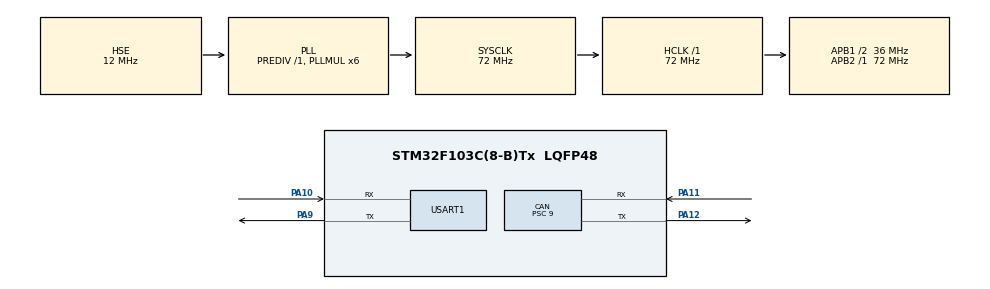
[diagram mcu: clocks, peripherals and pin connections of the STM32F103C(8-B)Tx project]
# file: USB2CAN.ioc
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Mcu.Family=STM32F1
Dma.MEMTOMEM.2.PeriphInc=DMA_PINC_ENABLE
RCC.PLLSourceVirtual=RCC_PLLSOURCE_HSE
Dma.USART1_TX.1.Instance=DMA1_Channel4
Dma.MEMTOMEM.2.MemDataAlignment=DMA_MDATAALIGN_BYTE
NVIC.DMA1_Channel5_IRQn=true\:0\:0\:false\:false\:true\:false\:true
Dma.USART1_RX.0.PeriphDataAlignment=DMA_PDATAALIGN_BYTE
PD1-OSC_OUT.Mode=HSE-External-Oscillator
PA10.Mode=Asynchronous
Dma.USART1_TX.1.MemInc=DMA_MINC_ENABLE
Dma.MEMTOMEM.2.Instance=DMA1_Channel1
PA11.Mode=Master
PD0-OSC_IN.Signal=RCC_OSC_IN
RCC.APB1CLKDivider=RCC_HCLK_DIV2
CAN.CalculateTimeBit=4000
RCC.SYSCLKSource=RCC_SYSCLKSOURCE_PLLCLK
ProjectManager.StackSize=0x400
PD1-OSC_OUT.Signal=RCC_OSC_OUT
Dma.MEMTOMEM.2.Priority=DMA_PRIORITY_LOW
PA13.Signal=SYS_JTMS-SWDIO
PA9.Mode=Asynchronous
PA12.Signal=CAN_TX
CAN.BS2=CAN_BS2_8TQ
CAN.Prescaler=9
CAN.BS1=CAN_BS1_7TQ
ProjectManager.TargetToolchain=MDK-ARM V5.27
Dma.USART1_RX.0.Direction=DMA_PERIPH_TO_MEMORY
RCC.HCLKFreq_Value=72000000
RCC.APB2TimFreq_Value=72000000
PA9.Signal=USART1_TX
Dma.MEMTOMEM.2.PeriphDataAlignment=DMA_PDATAALIGN_BYTE
RCC.USBFreq_Value=72000000
CAN.Mode=CAN_MODE_LOOPBACK
RCC.AHBFreq_Value=72000000
Dma.USART1_RX.0.PeriphInc=DMA_PINC_DISABLE
Dma.USART1_RX.0.Priority=DMA_PRIORITY_MEDIUM
PD0-OSC_IN.Mode=HSE-External-Oscillator
RCC.HSE_VALUE=12000000
Dma.MEMTOMEM.2.MemInc=DMA_MINC_ENABLE
Dma.USART1_TX.1.MemDataAlignment=DMA_MDATAALIGN_BYTE
board=custom
RCC.PLLMUL=RCC_PLL_MUL6
RCC.APB2Freq_Value=72000000
Dma.MEMTOMEM.2.Mode=DMA_NORMAL
PA14.Mode=Serial_Wire
NVIC.USB_LP_CAN1_RX0_IRQn=true\:0\:0\:false\:false\:true\:true\:true
Dma.USART1_RX.0.MemDataAlignment=DMA_MDATAALIGN_BYTE
Dma.MEMTOMEM.2.Direction=DMA_MEMORY_TO_MEMORY
Dma.USART1_RX.0.MemInc=DMA_MINC_ENABLE
PA13.Mode=Serial_Wire
Mcu.Name=STM32F103C(8-B)Tx
CAN.CalculateTimeQuantum=250.0
Dma.USART1_TX.1.PeriphDataAlignment=DMA_PDATAALIGN_BYTE
RCC.SYSCLKFreq_VALUE=72000000
Mcu.Package=LQFP48
PA12.Mode=Master
Dma.USART1_TX.1.Mode=DMA_NORMAL
USART1.VirtualMode=VM_ASYNC
PA11.Signal=CAN_RX
PA14.Signal=SYS_JTCK-SWCLK
PA10.Signal=USART1_RX
ProjectManager.HeapSize=0x200
Dma.USART1_TX.1.PeriphInc=DMA_PINC_DISABLE
NVIC.PriorityGroup=NVIC_PRIORITYGROUP_2
Dma.Request2=MEMTOMEM
Dma.Request1=USART1_TX
RCC.APB1TimFreq_Value=72000000
Dma.USART1_RX.0.Mode=DMA_NORMAL
Dma.USART1_TX.1.Priority=DMA_PRIORITY_MEDIUM
NVIC.DMA1_Channel4_IRQn=true\:0\:0\:false\:false\:true\:false\:true
NVIC.USART1_IRQn=true\:0\:0\:false\:false\:true\:true\:true
Dma.Request0=USART1_RX
RCC.APB1Freq_Value=36000000
Dma.USART1_RX.0.Instance=DMA1_Channel5
Dma.USART1_TX.1.Direction=DMA_MEMORY_TO_PERIPH

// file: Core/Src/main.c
/* USER CODE BEGIN Header */
/**
  ******************************************************************************
  * @file           : main.c
  * @brief          : Main program body
  * @author			: zhuyuhao
  ******************************************************************************
  * @attention
  *
  * 该程序用于TF02与PC机的CAN转USB通信转接板
  *
  * 环境配置：
  *	TF02的数据通过can发送，默认波特率250K；
  * PC端通过串口接受，需要安装CP2105的驱动，默认波特率115200。
  *
  * 程序功能：
  * 接受PC端串口数据，通过CAN发送给雷达，最大一次可以发送100字节。
  * 接受雷达端CAN数据，通过串口发送给PC机。
  * 打开main.h内的宏定义TEST_MODE，可通过CAN的回环模式在串口查看测试数据，此时无法连接雷达。
  *
  ******************************************************************************
  */
/* USER CODE END Header */
#include "main.h"
#include "can.h"
#include "dma.h"
#include "usart.h"
#include "gpio.h"

/* USER CODE BEGIN Includes */

#include "stdio.h"
#include "string.h"
#include "if.h"

/* USER CODE END Includes */

void SystemClock_Config(void);

int main(void)
{

    /* MCU Configuration--------------------------------------------------------*/

    /* Reset of all peripherals, Initializes the Flash interface and the Systick. */
    HAL_Init();

    /* Configure the system clock */
    SystemClock_Config();

    /* Initialize all configured peripherals */
    MX_GPIO_Init();
    MX_DMA_Init();
    MX_CAN_Init();
    MX_USART1_UART_Init();
    /* USER CODE BEGIN 2 */

    CAN_INIT();
    Usart_Bspinit();

#ifdef TEST_MODE
    printf("\r\n\r\ninit!\r\n");
#endif

    /* USER CODE END 2 */

    /* Infinite loop */
    /* USER CODE BEGIN WHILE */
    while (1)
    {
        run();
        /* USER CODE END WHILE */

    }
}

void SystemClock_Config(void)
{
    RCC_OscInitTypeDef RCC_OscInitStruct = {0};
    RCC_ClkInitTypeDef RCC_ClkInitStruct = {0};

    /** Initializes the RCC Oscillators according to the specified parameters
    * in the RCC_OscInitTypeDef structure.
    */
    RCC_OscInitStruct.OscillatorType = RCC_OSCILLATORTYPE_HSE;
    RCC_OscInitStruct.HSEState = RCC_HSE_ON;
    RCC_OscInitStruct.HSEPredivValue = RCC_HSE_PREDIV_DIV1;
    RCC_OscInitStruct.HSIState = RCC_HSI_ON;
    RCC_OscInitStruct.PLL.PLLState = RCC_PLL_ON;
    RCC_OscInitStruct.PLL.PLLSource = RCC_PLLSOURCE_HSE;
    RCC_OscInitStruct.PLL.PLLMUL = RCC_PLL_MUL6;
    if (HAL_RCC_OscConfig(&RCC_OscInitStruct) != HAL_OK)
    {
        Error_Handler();
    }
    /** Initializes the CPU, AHB and APB buses clocks
    */
    RCC_ClkInitStruct.ClockType = RCC_CLOCKTYPE_HCLK|RCC_CLOCKTYPE_SYSCLK
                                  |RCC_CLOCKTYPE_PCLK1|RCC_CLOCKTYPE_PCLK2;
    RCC_ClkInitStruct.SYSCLKSource = RCC_SYSCLKSOURCE_PLLCLK;
    RCC_ClkInitStruct.AHBCLKDivider = RCC_SYSCLK_DIV1;
    RCC_ClkInitStruct.APB1CLKDivider = RCC_HCLK_DIV2;
    RCC_ClkInitStruct.APB2CLKDivider = RCC_HCLK_DIV1;

    if (HAL_RCC_ClockConfig(&RCC_ClkInitStruct, FLASH_LATENCY_2) != HAL_OK)
    {
        Error_Handler();
    }
}

void Error_Handler(void)
{
}

/************************ (C) COPYRIGHT STMicroelectronics *****END OF FILE****/
